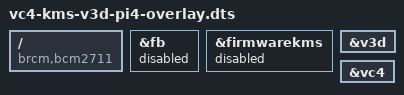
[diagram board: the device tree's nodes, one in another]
// SPDX-License-Identifier: GPL-2.0
/dts-v1/;
/plugin/;

/ {
	compatible = "brcm,bcm2711";
	
	fragment@1 {
		target = <&fb>;
		__overlay__ {
			status = "disabled";
		};
	};
	
	fragment@2 {
		target = <&firmwarekms>;
		__overlay__ {
			status = "disabled";
		};
	};
	
	fragment@3 {
		target = <&v3d>;
		__overlay__ {
			status = "okay";
		};
	};
	
	fragment@4 {
		target = <&vc4>;
		__overlay__ {
			status = "okay";
		};
	};
};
